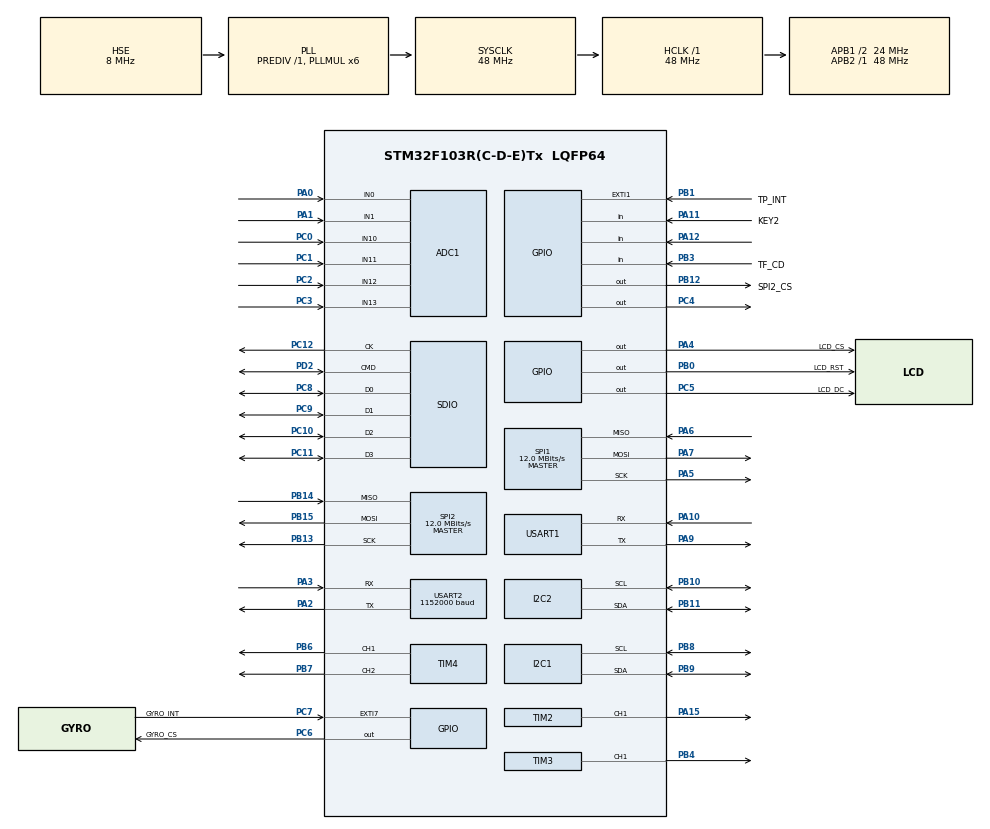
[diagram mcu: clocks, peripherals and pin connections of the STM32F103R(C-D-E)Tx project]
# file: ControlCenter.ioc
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ADC1.Channel-4\#ChannelRegularConversion=ADC_CHANNEL_10
ADC1.NbrOfConversionFlag=1
ADC1.Rank-4\#ChannelRegularConversion=1
ADC1.SamplingTime-4\#ChannelRegularConversion=ADC_SAMPLETIME_1CYCLE_5
ADC1.master=1
Dma.Request0=USART1_RX
Dma.Request1=USART1_TX
Dma.USART1_RX.0.Direction=DMA_PERIPH_TO_MEMORY
Dma.USART1_RX.0.Instance=DMA1_Channel5
Dma.USART1_RX.0.MemDataAlignment=DMA_MDATAALIGN_BYTE
Dma.USART1_RX.0.MemInc=DMA_MINC_ENABLE
Dma.USART1_RX.0.Mode=DMA_NORMAL
Dma.USART1_RX.0.PeriphDataAlignment=DMA_PDATAALIGN_BYTE
Dma.USART1_RX.0.PeriphInc=DMA_PINC_DISABLE
Dma.USART1_RX.0.Priority=DMA_PRIORITY_LOW
Dma.USART1_TX.1.Direction=DMA_MEMORY_TO_PERIPH
Dma.USART1_TX.1.Instance=DMA1_Channel4
Dma.USART1_TX.1.MemDataAlignment=DMA_MDATAALIGN_BYTE
Dma.USART1_TX.1.MemInc=DMA_MINC_ENABLE
Dma.USART1_TX.1.Mode=DMA_NORMAL
Dma.USART1_TX.1.PeriphDataAlignment=DMA_PDATAALIGN_BYTE
Dma.USART1_TX.1.PeriphInc=DMA_PINC_DISABLE
Dma.USART1_TX.1.Priority=DMA_PRIORITY_LOW
FREERTOS.Tasks01=defaultTask,0,128,StartDefaultTask,Default,NULL,Dynamic,NULL,NULL
Mcu.Family=STM32F1
Mcu.Name=STM32F103R(C-D-E)Tx
Mcu.Package=LQFP64
NVIC.DMA1_Channel4_IRQn=true\:5\:0\:false\:false\:true\:true\:false\:true\:true
NVIC.DMA1_Channel5_IRQn=true\:5\:0\:false\:false\:true\:true\:false\:true\:true
NVIC.PriorityGroup=NVIC_PRIORITYGROUP_4
NVIC.TIM1_UP_IRQn=true\:15\:0\:false\:false\:true\:false\:false\:true\:true
NVIC.TimeBase=TIM1_UP_IRQn
NVIC.TimeBaseIP=TIM1
NVIC.USART1_IRQn=true\:5\:0\:false\:false\:true\:true\:false\:true\:true
PA0-WKUP.Signal=ADCx_IN0
PA1.Signal=ADCx_IN1
PA10.Mode=Asynchronous
PA10.Signal=USART1_RX
PA11.GPIO_Label=KEY2
PA11.GPIO_PuPd=GPIO_PULLUP
PA11.Signal=GPIO_Input
PA12.Signal=GPIO_Input
PA13.Mode=Serial_Wire
PA13.Signal=SYS_JTMS-SWDIO
PA14.Mode=Serial_Wire
PA14.Signal=SYS_JTCK-SWCLK
PA15.Signal=S_TIM2_CH1_ETR
PA2.Mode=Asynchronous
PA2.Signal=USART2_TX
PA3.Mode=Asynchronous
PA3.Signal=USART2_RX
PA4.GPIO_Label=LCD_CS
PA4.GPIO_PuPd=GPIO_PULLUP
PA4.GPIO_Speed=GPIO_SPEED_FREQ_HIGH
PA4.PinState=GPIO_PIN_SET
PA4.Signal=GPIO_Output
PA5.Mode=Full_Duplex_Master
PA5.Signal=SPI1_SCK
PA6.Mode=Full_Duplex_Master
PA6.Signal=SPI1_MISO
PA7.Mode=Full_Duplex_Master
PA7.Signal=SPI1_MOSI
PA9.Mode=Asynchronous
PA9.Signal=USART1_TX
PB0.GPIO_Label=LCD_RST
PB0.GPIO_PuPd=GPIO_PULLUP
PB0.GPIO_Speed=GPIO_SPEED_FREQ_LOW
PB0.PinState=GPIO_PIN_SET
PB0.Signal=GPIO_Output
PB1.GPIO_Label=TP_INT
PB1.GPIO_PuPd=GPIO_PULLUP
PB1.Signal=GPXTI1
PB10.Mode=I2C
PB10.Signal=I2C2_SCL
PB11.Mode=I2C
PB11.Signal=I2C2_SDA
PB12.GPIO_Label=SPI2_CS
PB12.GPIO_PuPd=GPIO_PULLUP
PB12.GPIO_Speed=GPIO_SPEED_FREQ_HIGH
PB12.PinState=GPIO_PIN_SET
PB12.Signal=GPIO_Output
PB13.Mode=Full_Duplex_Master
PB13.Signal=SPI2_SCK
PB14.Mode=Full_Duplex_Master
PB14.Signal=SPI2_MISO
PB15.Mode=Full_Duplex_Master
PB15.Signal=SPI2_MOSI
PB3.GPIO_Label=TF_CD
PB3.GPIO_PuPd=GPIO_PULLUP
PB3.Signal=GPIO_Input
PB4.Signal=S_TIM3_CH1
PB6.Signal=S_TIM4_CH1
PB7.Signal=S_TIM4_CH2
PB8.Mode=I2C
PB8.Signal=I2C1_SCL
PB9.Mode=I2C
PB9.Signal=I2C1_SDA
PC0.Signal=ADCx_IN10
PC1.Signal=ADCx_IN11
PC10.Mode=SD_4_bits_Wide_bus
PC10.Signal=SDIO_D2
PC11.Mode=SD_4_bits_Wide_bus
PC11.Signal=SDIO_D3
PC12.Mode=SD_4_bits_Wide_bus
PC12.Signal=SDIO_CK
PC14-OSC32_IN.Mode=LSE-External-Oscillator
PC14-OSC32_IN.Signal=RCC_OSC32_IN
PC15-OSC32_OUT.Mode=LSE-External-Oscillator
PC15-OSC32_OUT.Signal=RCC_OSC32_OUT
PC2.Signal=ADCx_IN12
PC3.Signal=ADCx_IN13
PC4.Signal=GPIO_Output
PC5.GPIO_Label=LCD_DC
PC5.GPIO_PuPd=GPIO_PULLUP
PC5.GPIO_Speed=GPIO_SPEED_FREQ_HIGH
PC5.PinState=GPIO_PIN_SET
PC5.Signal=GPIO_Output
PC6.GPIO_Label=GYRO_CS
PC6.GPIO_PuPd=GPIO_PULLUP
PC6.GPIO_Speed=GPIO_SPEED_FREQ_HIGH
PC6.PinState=GPIO_PIN_SET
PC6.Signal=GPIO_Output
PC7.GPIO_Label=GYRO_INT
PC7.GPIO_PuPd=GPIO_PULLUP
PC7.Signal=GPXTI7
PC8.Mode=SD_4_bits_Wide_bus
PC8.Signal=SDIO_D0
PC9.Mode=SD_4_bits_Wide_bus
PC9.Signal=SDIO_D1
PD0-OSC_IN.Mode=HSE-External-Oscillator
PD0-OSC_IN.Signal=RCC_OSC_IN
PD1-OSC_OUT.Mode=HSE-External-Oscillator
PD1-OSC_OUT.Signal=RCC_OSC_OUT
PD2.Mode=SD_4_bits_Wide_bus
PD2.Signal=SDIO_CMD
ProjectManager.HeapSize=0x200
ProjectManager.StackSize=0x400
ProjectManager.TargetToolchain=MDK-ARM V5.32
RCC.ADCPresc=RCC_ADCPCLK2_DIV6
RCC.AHBFreq_Value=48000000
RCC.APB1CLKDivider=RCC_HCLK_DIV2
RCC.APB1Freq_Value=24000000
RCC.APB1TimFreq_Value=48000000
RCC.APB2Freq_Value=48000000
RCC.APB2TimFreq_Value=48000000
RCC.HCLKFreq_Value=48000000
RCC.PLLMUL=RCC_PLL_MUL6
RCC.PLLSourceVirtual=RCC_PLLSOURCE_HSE
RCC.RTCClockSelection=RCC_RTCCLKSOURCE_LSE
RCC.SYSCLKFreq_VALUE=48000000
RCC.SYSCLKSource=RCC_SYSCLKSOURCE_PLLCLK
RCC.USBFreq_Value=48000000
SH.ADCx_IN0.0=ADC1_IN0,IN0
SH.ADCx_IN1.0=ADC1_IN1,IN1
SH.ADCx_IN10.0=ADC1_IN10,IN10
SH.ADCx_IN11.0=ADC1_IN11,IN11
SH.ADCx_IN12.0=ADC1_IN12,IN12
SH.ADCx_IN13.0=ADC1_IN13,IN13
SH.S_TIM2_CH1_ETR.0=TIM2_CH1,PWM Generation1 CH1
SH.S_TIM3_CH1.0=TIM3_CH1,PWM Generation1 CH1
SH.S_TIM4_CH1.0=TIM4_CH1,PWM Generation1 CH1
SH.S_TIM4_CH2.0=TIM4_CH2,PWM Generation2 CH2
SPI1.BaudRatePrescaler=SPI_BAUDRATEPRESCALER_4
SPI1.CalculateBaudRate=12.0 MBits/s
SPI1.Direction=SPI_DIRECTION_2LINES
SPI1.Mode=SPI_MODE_MASTER
SPI1.VirtualType=VM_MASTER
SPI2.CalculateBaudRate=12.0 MBits/s
SPI2.Direction=SPI_DIRECTION_2LINES
SPI2.Mode=SPI_MODE_MASTER
SPI2.VirtualType=VM_MASTER
TIM2.Channel-PWM\ Generation1\ CH1=TIM_CHANNEL_1
TIM3.Channel-PWM\ Generation1\ CH1=TIM_CHANNEL_1
TIM4.Channel-PWM\ Generation1\ CH1=TIM_CHANNEL_1
TIM4.Channel-PWM\ Generation2\ CH2=TIM_CHANNEL_2
USART1.VirtualMode=VM_ASYNC
USART2.BaudRate=1152000
USART2.VirtualMode=VM_ASYNC
VP_ADC1_TempSens_Input.Mode=IN-TempSens
VP_CRC_VS_CRC.Mode=CRC_Activate
VP_FREERTOS_VS_CMSIS_V1.Mode=CMSIS_V1
VP_RTC_VS_RTC_Activate.Mode=RTC_Enabled
VP_RTC_VS_RTC_Calendar.Mode=RTC_Calendar
VP_SYS_VS_tim1.Mode=TIM1
board=custom

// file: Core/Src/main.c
/* USER CODE BEGIN Header */
/**
 ******************************************************************************
 * @file           : main.c
 * @brief          : Main program body
 ******************************************************************************
 * @attention
 *
 * Copyright (c) 2025 STMicroelectronics.
 * All rights reserved.
 *
 * This software is licensed under terms that can be found in the LICENSE file
 * in the root directory of this software component.
 * If no LICENSE file comes with this software, it is provided AS-IS.
 *
 ******************************************************************************
 */
/* USER CODE END Header */
#include "main.h"
#include "cmsis_os.h"
#include "adc.h"
#include "crc.h"
#include "dma.h"
#include "i2c.h"
#include "rtc.h"
#include "sdio.h"
#include "spi.h"
#include "tim.h"
#include "usart.h"
#include "gpio.h"

/* USER CODE BEGIN PV */
char testChar[] = "sesame\r\n";
/* USER CODE END PV */

void SystemClock_Config(void);
void MX_FREERTOS_Init(void);

int main(void)
{

  /* MCU Configuration--------------------------------------------------------*/

  /* Reset of all peripherals, Initializes the Flash interface and the Systick. */
  HAL_Init();

  /* Configure the system clock */
  SystemClock_Config();

  /* Initialize all configured peripherals */
  MX_GPIO_Init();
  MX_DMA_Init();
  MX_USART1_UART_Init();
  MX_ADC1_Init();
  MX_CRC_Init();
  MX_I2C2_Init();
  MX_SPI1_Init();
  MX_I2C1_Init();
  MX_RTC_Init();
  MX_SDIO_SD_Init();
  MX_SPI2_Init();
  MX_TIM2_Init();
  MX_TIM3_Init();
  MX_TIM4_Init();
  MX_USART2_UART_Init();
  /* USER CODE BEGIN 2 */
	HAL_UART_Transmit(&huart2,testChar,sizeof(testChar),0xffff);
  /* USER CODE END 2 */

  /* Call init function for freertos objects (in cmsis_os2.c) */
  MX_FREERTOS_Init();

  /* Start scheduler */
  osKernelStart();

  /* We should never get here as control is now taken by the scheduler */

  /* Infinite loop */
  while (1)
  {

  }
}

void SystemClock_Config(void)
{
  RCC_OscInitTypeDef RCC_OscInitStruct = {0};
  RCC_ClkInitTypeDef RCC_ClkInitStruct = {0};
  RCC_PeriphCLKInitTypeDef PeriphClkInit = {0};

  /** Initializes the RCC Oscillators according to the specified parameters
  * in the RCC_OscInitTypeDef structure.
  */
  RCC_OscInitStruct.OscillatorType = RCC_OSCILLATORTYPE_HSE|RCC_OSCILLATORTYPE_LSE;
  RCC_OscInitStruct.HSEState = RCC_HSE_ON;
  RCC_OscInitStruct.HSEPredivValue = RCC_HSE_PREDIV_DIV1;
  RCC_OscInitStruct.LSEState = RCC_LSE_ON;
  RCC_OscInitStruct.HSIState = RCC_HSI_ON;
  RCC_OscInitStruct.PLL.PLLState = RCC_PLL_ON;
  RCC_OscInitStruct.PLL.PLLSource = RCC_PLLSOURCE_HSE;
  RCC_OscInitStruct.PLL.PLLMUL = RCC_PLL_MUL6;
  if (HAL_RCC_OscConfig(&RCC_OscInitStruct) != HAL_OK)
  {
    Error_Handler();
  }

  /** Initializes the CPU, AHB and APB buses clocks
  */
  RCC_ClkInitStruct.ClockType = RCC_CLOCKTYPE_HCLK|RCC_CLOCKTYPE_SYSCLK
                              |RCC_CLOCKTYPE_PCLK1|RCC_CLOCKTYPE_PCLK2;
  RCC_ClkInitStruct.SYSCLKSource = RCC_SYSCLKSOURCE_PLLCLK;
  RCC_ClkInitStruct.AHBCLKDivider = RCC_SYSCLK_DIV1;
  RCC_ClkInitStruct.APB1CLKDivider = RCC_HCLK_DIV2;
  RCC_ClkInitStruct.APB2CLKDivider = RCC_HCLK_DIV1;

  if (HAL_RCC_ClockConfig(&RCC_ClkInitStruct, FLASH_LATENCY_1) != HAL_OK)
  {
    Error_Handler();
  }
  PeriphClkInit.PeriphClockSelection = RCC_PERIPHCLK_RTC|RCC_PERIPHCLK_ADC;
  PeriphClkInit.RTCClockSelection = RCC_RTCCLKSOURCE_LSE;
  PeriphClkInit.AdcClockSelection = RCC_ADCPCLK2_DIV6;
  if (HAL_RCCEx_PeriphCLKConfig(&PeriphClkInit) != HAL_OK)
  {
    Error_Handler();
  }
}

void HAL_TIM_PeriodElapsedCallback(TIM_HandleTypeDef *htim)
{
  if (htim->Instance == TIM1)
  {
    HAL_IncTick();
  }
}

void Error_Handler(void)
{
  __disable_irq();
  while (1)
  {
  }
}
